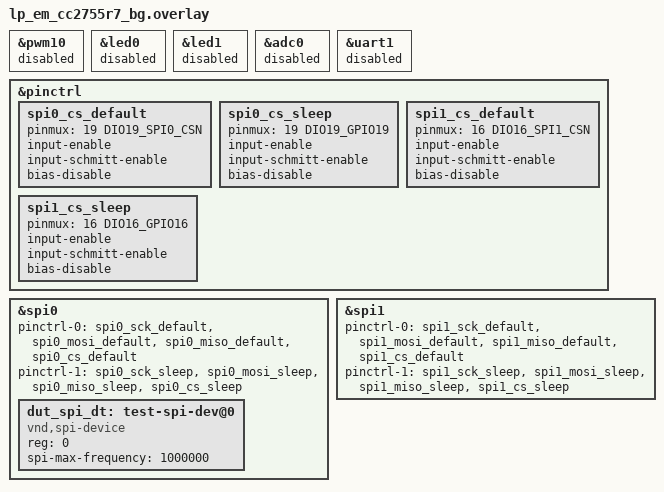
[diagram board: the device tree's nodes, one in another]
/*
 * Copyright (c) 2026 Texas Instruments Incorporated
 *
 * SPDX-License-Identifier: Apache-2.0
 */

&pwm10 {
	status = "disabled";
};

&led0 {
	status = "disabled";
};

&led1 {
	status = "disabled";
};

&adc0 {
	status = "disabled";
};

&uart1 {
	status = "disabled";
};

&pinctrl {
	spi0_cs_default: spi0_cs_default {
		pinmux = <19 DIO19_SPI0_CSN>;
		input-enable;
		input-schmitt-enable;
		bias-disable;
	};

	spi0_cs_sleep: spi0_cs_sleep {
		pinmux = <19 DIO19_GPIO19>;
		input-enable;
		input-schmitt-enable;
		bias-disable;
	};
};

&pinctrl {
	spi1_cs_default: spi1_cs_default {
		pinmux = <16 DIO16_SPI1_CSN>;
		input-enable;
		input-schmitt-enable;
		bias-disable;
	};

	spi1_cs_sleep: spi1_cs_sleep {
		pinmux = <16 DIO16_GPIO16>;
		input-enable;
		input-schmitt-enable;
		bias-disable;
	};
};

&spi0 {
	status = "okay";
	pinctrl-0 = <&spi0_sck_default
		     &spi0_mosi_default
		     &spi0_miso_default
		     &spi0_cs_default>;
	pinctrl-1 = <&spi0_sck_sleep
		     &spi0_mosi_sleep
		     &spi0_miso_sleep
		     &spi0_cs_sleep>;
	pinctrl-names = "default", "sleep";
	/delete-property/ cs-gpios;

	dut_spi_dt: test-spi-dev@0 {
		compatible = "vnd,spi-device";
		reg = <0>;
		spi-max-frequency = <1000000>;
	};
};

dut_spis: &spi1 {
	status = "okay";
	pinctrl-0 = <&spi1_sck_default
		     &spi1_mosi_default
		     &spi1_miso_default
		     &spi1_cs_default>;
	pinctrl-1 = <&spi1_sck_sleep
		     &spi1_mosi_sleep
		     &spi1_miso_sleep
		     &spi1_cs_sleep>;
	pinctrl-names = "default", "sleep";
};
